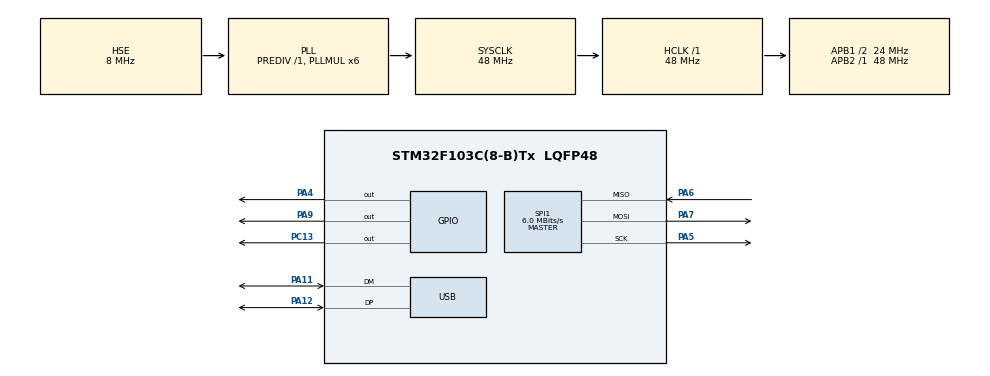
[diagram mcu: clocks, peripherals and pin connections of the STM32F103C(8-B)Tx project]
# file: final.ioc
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Mcu.Family=STM32F1
Mcu.Name=STM32F103C(8-B)Tx
Mcu.Package=LQFP48
NVIC.PriorityGroup=NVIC_PRIORITYGROUP_4
NVIC.USB_LP_CAN1_RX0_IRQn=true\:0\:0\:false\:false\:true\:false\:true\:true
PA11.Mode=Device
PA11.Signal=USB_DM
PA12.Mode=Device
PA12.Signal=USB_DP
PA13.Mode=Serial_Wire
PA13.Signal=SYS_JTMS-SWDIO
PA14.Mode=Serial_Wire
PA14.Signal=SYS_JTCK-SWCLK
PA4.Signal=GPIO_Output
PA5.Mode=Full_Duplex_Master
PA5.Signal=SPI1_SCK
PA6.Mode=Full_Duplex_Master
PA6.Signal=SPI1_MISO
PA7.Mode=Full_Duplex_Master
PA7.Signal=SPI1_MOSI
PA9.Signal=GPIO_Output
PC13-TAMPER-RTC.Signal=GPIO_Output
PD0-OSC_IN.Mode=HSE-External-Oscillator
PD0-OSC_IN.Signal=RCC_OSC_IN
PD1-OSC_OUT.Mode=HSE-External-Oscillator
PD1-OSC_OUT.Signal=RCC_OSC_OUT
ProjectManager.HeapSize=0x200
ProjectManager.StackSize=0x400
ProjectManager.TargetToolchain=MDK-ARM V5
RCC.AHBFreq_Value=48000000
RCC.APB1CLKDivider=RCC_HCLK_DIV2
RCC.APB1Freq_Value=24000000
RCC.APB1TimFreq_Value=48000000
RCC.APB2Freq_Value=48000000
RCC.APB2TimFreq_Value=48000000
RCC.HCLKFreq_Value=48000000
RCC.PLLMUL=RCC_PLL_MUL6
RCC.SYSCLKFreq_VALUE=48000000
RCC.SYSCLKSource=RCC_SYSCLKSOURCE_PLLCLK
RCC.USBFreq_Value=48000000
SPI1.BaudRatePrescaler=SPI_BAUDRATEPRESCALER_8
SPI1.CalculateBaudRate=6.0 MBits/s
SPI1.Direction=SPI_DIRECTION_2LINES
SPI1.Mode=SPI_MODE_MASTER
SPI1.VirtualType=VM_MASTER
USB_DEVICE.CLASS_NAME_FS=HID
USB_DEVICE.PRODUCT_STRING_HID_FS=RFID Reader
USB_DEVICE.VirtualMode=Hid
USB_DEVICE.VirtualModeFS=Hid_FS
VP_USB_DEVICE_VS_USB_DEVICE_HID_FS.Mode=HID_FS
board=custom

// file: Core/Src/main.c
/* USER CODE BEGIN Header */
/**
  ******************************************************************************
  * @file           : main.c
  * @brief          : Main program body
  ******************************************************************************
  * @attention
  *
  * Copyright (c) 2024 STMicroelectronics.
  * All rights reserved.
  *
  * This software is licensed under terms that can be found in the LICENSE file
  * in the root directory of this software component.
  * If no LICENSE file comes with this software, it is provided AS-IS.
  *
  ******************************************************************************
  */
/* USER CODE END Header */
#include "main.h"
#include "usb_device.h"
#include "usbd_hid.h"
#include "stm32f1_rc522.h"
uint8_t str[16];
uint8_t result[6] = {
	0, //MODIFIER
	0, //RESERVED
	0, //KEYCODE1
	0, //KEYCODE2
	0, //KEYCODE3
	0 //KEYCODE4
};
extern USBD_HandleTypeDef hUsbDeviceFS;

SPI_HandleTypeDef hspi1;

void SystemClock_Config(void);
static void MX_GPIO_Init(void);
static void MX_SPI1_Init(void);

int main(void)
{

  /* MCU Configuration--------------------------------------------------------*/

  /* Reset of all peripherals, Initializes the Flash interface and the Systick. */
  HAL_Init();

  /* Configure the system clock */
  SystemClock_Config();

  /* Initialize all configured peripherals */
  MX_GPIO_Init();
  MX_SPI1_Init();
  MX_USB_DEVICE_Init();

  /* Infinite loop */
  while (1)
  {
		result[2] = 0x1E;
    /* USER CODE BEGIN 3 */
		if(result[2])
		{
			result[3] = 0x1F;
			result[4] = 0x20;
			result[5] = 0x21;
			USBD_HID_SendReport(&hUsbDeviceFS, result, sizeof (result)); // gui ki tu
			HAL_Delay(50);
			for(int i = 2; i <= 5; i++)
				result[i] = 0;
			USBD_HID_SendReport(&hUsbDeviceFS, result, sizeof (result)); // dung gui ki tu
			HAL_Delay(50);
		}
//		if ((!MFRC522_Request(PICC_REQIDL, str))) {
//	  		  if (MFRC522_Anticoll(str) == MI_OK) {
//						HAL_GPIO_WritePin(GPIOA, GPIO_PIN_9, GPIO_PIN_SET);
//						HAL_Delay(100);
//						HAL_GPIO_WritePin(GPIOA, GPIO_PIN_9, GPIO_PIN_RESET);
//	  			  HAL_GPIO_WritePin(GPIOC, GPIO_PIN_13, GPIO_PIN_RESET);
//	  			  HAL_Delay(500);
//	  			  HAL_GPIO_WritePin(GPIOC, GPIO_PIN_13, GPIO_PIN_SET);
//	  			  HAL_Delay(1000);
//						for(int i = 1; i <= 4; i++){
//							for(int j = 2; j <= 5; j++){
//								unsigned int a = (j-2)*2;
//								unsigned int b = (6-(j-2)*2);
//								result[j] = (str[i]&(0xC0>>a)) >> b;
//							}
//							for(int j = 2; j <= 5; j++){
//								if(!result[j])
//									result[j] = 0x27;
//								else
//									result[j] += 0x1D;
//							}
//							USBD_HID_SendReport(&hUsbDeviceFS, result, sizeof (result)); // gui ki tu
//							for(int i = 2; i <= 5; i++)
//								result[i] = 0;
//							USBD_HID_SendReport(&hUsbDeviceFS, result, sizeof (result)); // dung gui ki tu
//						}
//
//	  		  }
//		}
//    /* USER CODE BEGIN 3 */
  }
  /* USER CODE END 3 */
}

void SystemClock_Config(void)
{
  RCC_OscInitTypeDef RCC_OscInitStruct = {0};
  RCC_ClkInitTypeDef RCC_ClkInitStruct = {0};
  RCC_PeriphCLKInitTypeDef PeriphClkInit = {0};

  /** Initializes the RCC Oscillators according to the specified parameters
  * in the RCC_OscInitTypeDef structure.
  */
  RCC_OscInitStruct.OscillatorType = RCC_OSCILLATORTYPE_HSE;
  RCC_OscInitStruct.HSEState = RCC_HSE_ON;
  RCC_OscInitStruct.HSEPredivValue = RCC_HSE_PREDIV_DIV1;
  RCC_OscInitStruct.HSIState = RCC_HSI_ON;
  RCC_OscInitStruct.PLL.PLLState = RCC_PLL_ON;
  RCC_OscInitStruct.PLL.PLLSource = RCC_PLLSOURCE_HSE;
  RCC_OscInitStruct.PLL.PLLMUL = RCC_PLL_MUL6;
  if (HAL_RCC_OscConfig(&RCC_OscInitStruct) != HAL_OK)
  {
    Error_Handler();
  }

  /** Initializes the CPU, AHB and APB buses clocks
  */
  RCC_ClkInitStruct.ClockType = RCC_CLOCKTYPE_HCLK|RCC_CLOCKTYPE_SYSCLK
                              |RCC_CLOCKTYPE_PCLK1|RCC_CLOCKTYPE_PCLK2;
  RCC_ClkInitStruct.SYSCLKSource = RCC_SYSCLKSOURCE_PLLCLK;
  RCC_ClkInitStruct.AHBCLKDivider = RCC_SYSCLK_DIV1;
  RCC_ClkInitStruct.APB1CLKDivider = RCC_HCLK_DIV2;
  RCC_ClkInitStruct.APB2CLKDivider = RCC_HCLK_DIV1;

  if (HAL_RCC_ClockConfig(&RCC_ClkInitStruct, FLASH_LATENCY_1) != HAL_OK)
  {
    Error_Handler();
  }
  PeriphClkInit.PeriphClockSelection = RCC_PERIPHCLK_USB;
  PeriphClkInit.UsbClockSelection = RCC_USBCLKSOURCE_PLL;
  if (HAL_RCCEx_PeriphCLKConfig(&PeriphClkInit) != HAL_OK)
  {
    Error_Handler();
  }
}

static void MX_SPI1_Init(void)
{

  /* SPI1 parameter configuration*/
  hspi1.Instance = SPI1;
  hspi1.Init.Mode = SPI_MODE_MASTER;
  hspi1.Init.Direction = SPI_DIRECTION_2LINES;
  hspi1.Init.DataSize = SPI_DATASIZE_8BIT;
  hspi1.Init.CLKPolarity = SPI_POLARITY_LOW;
  hspi1.Init.CLKPhase = SPI_PHASE_1EDGE;
  hspi1.Init.NSS = SPI_NSS_SOFT;
  hspi1.Init.BaudRatePrescaler = SPI_BAUDRATEPRESCALER_8;
  hspi1.Init.FirstBit = SPI_FIRSTBIT_MSB;
  hspi1.Init.TIMode = SPI_TIMODE_DISABLE;
  hspi1.Init.CRCCalculation = SPI_CRCCALCULATION_DISABLE;
  hspi1.Init.CRCPolynomial = 10;
  if (HAL_SPI_Init(&hspi1) != HAL_OK)
  {
    Error_Handler();
  }

}

static void MX_GPIO_Init(void)
{
  GPIO_InitTypeDef GPIO_InitStruct = {0};

  /* GPIO Ports Clock Enable */
  __HAL_RCC_GPIOC_CLK_ENABLE();
  __HAL_RCC_GPIOD_CLK_ENABLE();
  __HAL_RCC_GPIOA_CLK_ENABLE();

  /*Configure GPIO pin Output Level */
  HAL_GPIO_WritePin(GPIOC, GPIO_PIN_13, GPIO_PIN_RESET);

  /*Configure GPIO pin Output Level */
  HAL_GPIO_WritePin(GPIOA, GPIO_PIN_4|GPIO_PIN_9, GPIO_PIN_RESET);

  /*Configure GPIO pin : PC13 */
  GPIO_InitStruct.Pin = GPIO_PIN_13;
  GPIO_InitStruct.Mode = GPIO_MODE_OUTPUT_PP;
  GPIO_InitStruct.Pull = GPIO_NOPULL;
  GPIO_InitStruct.Speed = GPIO_SPEED_FREQ_LOW;
  HAL_GPIO_Init(GPIOC, &GPIO_InitStruct);

  /*Configure GPIO pins : PA4 PA9 */
  GPIO_InitStruct.Pin = GPIO_PIN_4|GPIO_PIN_9;
  GPIO_InitStruct.Mode = GPIO_MODE_OUTPUT_PP;
  GPIO_InitStruct.Pull = GPIO_NOPULL;
  GPIO_InitStruct.Speed = GPIO_SPEED_FREQ_LOW;
  HAL_GPIO_Init(GPIOA, &GPIO_InitStruct);

}

void Error_Handler(void)
{
  __disable_irq();
  while (1)
  {
  }
}
